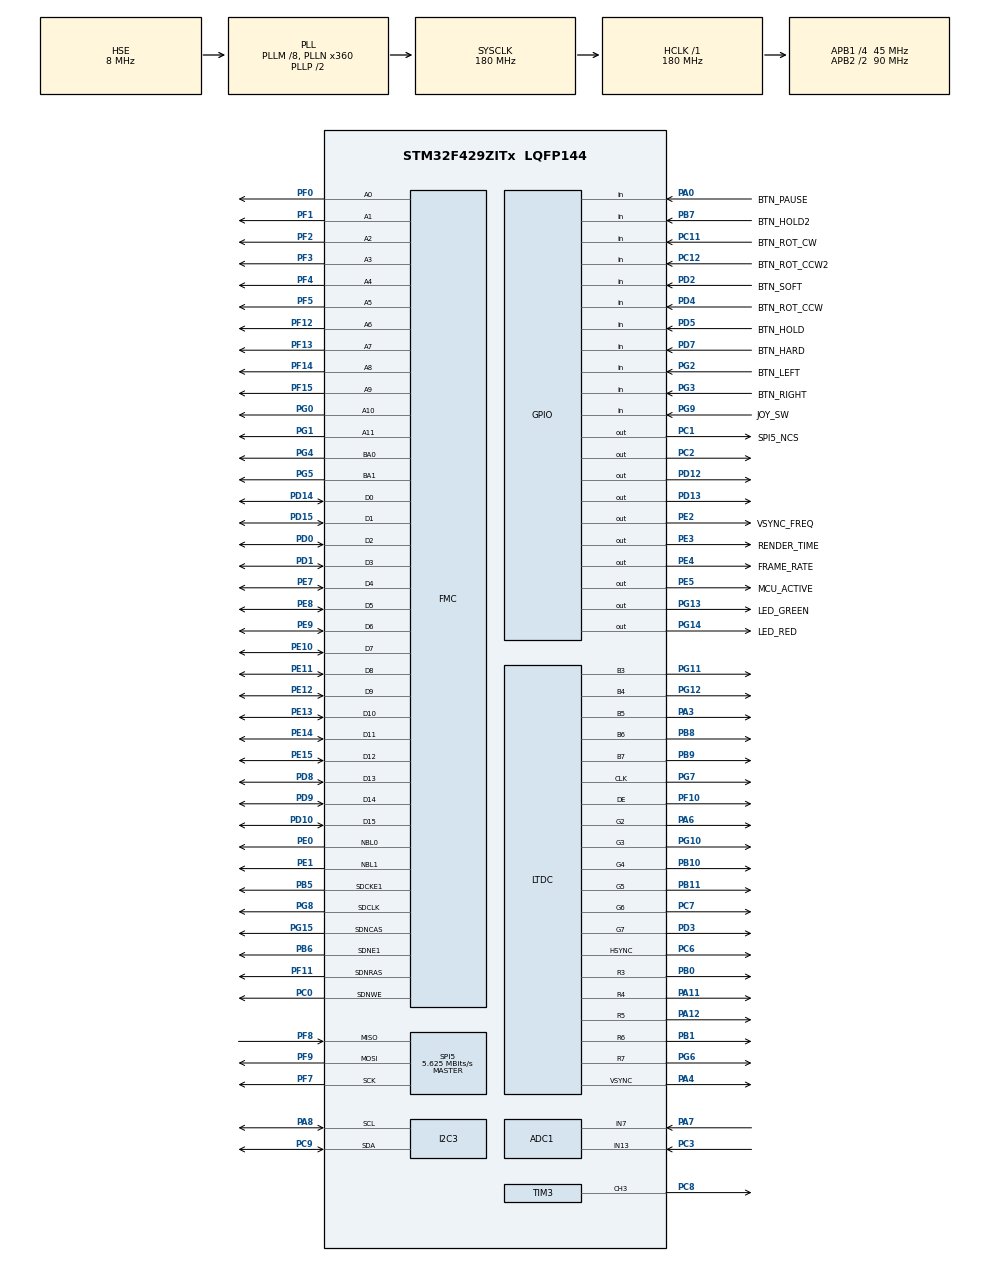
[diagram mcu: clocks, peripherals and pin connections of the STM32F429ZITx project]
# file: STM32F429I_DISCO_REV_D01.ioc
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ADC1.Channel-0\#ChannelRegularConversion=ADC_CHANNEL_13
ADC1.Channel-1\#ChannelRegularConversion=ADC_CHANNEL_7
ADC1.ContinuousConvMode=ENABLE
ADC1.DMAContinuousRequests=ENABLE
ADC1.NbrOfConversion=2
ADC1.NbrOfConversionFlag=1
ADC1.Rank-0\#ChannelRegularConversion=1
ADC1.Rank-1\#ChannelRegularConversion=2
ADC1.SamplingTime-0\#ChannelRegularConversion=ADC_SAMPLETIME_144CYCLES
ADC1.SamplingTime-1\#ChannelRegularConversion=ADC_SAMPLETIME_144CYCLES
ADC1.ScanConvMode=ENABLE
ADC1.master=1
DMA2D.ColorMode=DMA2D_OUTPUT_RGB565
Dma.ADC1.0.Direction=DMA_PERIPH_TO_MEMORY
Dma.ADC1.0.FIFOMode=DMA_FIFOMODE_DISABLE
Dma.ADC1.0.Instance=DMA2_Stream0
Dma.ADC1.0.MemDataAlignment=DMA_MDATAALIGN_HALFWORD
Dma.ADC1.0.MemInc=DMA_MINC_ENABLE
Dma.ADC1.0.Mode=DMA_CIRCULAR
Dma.ADC1.0.PeriphDataAlignment=DMA_PDATAALIGN_HALFWORD
Dma.ADC1.0.PeriphInc=DMA_PINC_DISABLE
Dma.ADC1.0.Priority=DMA_PRIORITY_LOW
Dma.Request0=ADC1
FMC.CASLatency1=FMC_SDRAM_CAS_LATENCY_3
FMC.ExitSelfRefreshDelay1=7
FMC.LoadToActiveDelay1=2
FMC.RCDDelay1=2
FMC.RPDelay1=2
FMC.ReadPipeDelay1=FMC_SDRAM_RPIPE_DELAY_1
FMC.RowCycleDelay1=7
FMC.SDClockPeriod1=FMC_SDRAM_CLOCK_PERIOD_2
FMC.SelfRefreshTime1=4
FMC.WriteRecoveryTime1=3
FREERTOS.Tasks01=defaultTask,24,128,StartDefaultTask,Default,NULL,Dynamic,NULL,NULL;GUI_Task,24,8192,TouchGFX_Task,As external,NULL,Dynamic,NULL,NULL
FREERTOS.configMAX_PRIORITIES=56
FREERTOS.configTOTAL_HEAP_SIZE=65536
FREERTOS.configUSE_APPLICATION_TASK_TAG=1
FREERTOS.configUSE_NEWLIB_REENTRANT=1
I2C3.Analog_Filter=I2C_ANALOGFILTER_DISABLE
LTDC.ActiveH=320
LTDC.ActiveW=240
LTDC.Alpha_L0=255
LTDC.BlendingFactor1_L0=LTDC_BLENDING_FACTOR1_CA
LTDC.BlendingFactor2_L0=LTDC_BLENDING_FACTOR2_CA
LTDC.Blue_L0=0
LTDC.HBP=20
LTDC.HFP=10
LTDC.HSync=10
LTDC.ImageHeight_L0=320
LTDC.ImageWidth_L0=240
LTDC.Layers=0
LTDC.PixelFormat_L0=LTDC_PIXEL_FORMAT_RGB565
LTDC.VFP=4
LTDC.VSync=2
LTDC.WindowX1_L0=240
LTDC.WindowY1_L0=320
Mcu.Family=STM32F4
Mcu.Name=STM32F429ZITx
Mcu.Package=LQFP144
NVIC.DMA2D_IRQn=true\:5\:0\:true\:false\:true\:false\:true\:true\:true
NVIC.DMA2_Stream0_IRQn=true\:5\:0\:false\:false\:true\:true\:false\:true\:true
NVIC.LTDC_IRQn=true\:5\:0\:true\:false\:true\:false\:true\:true\:true
NVIC.PriorityGroup=NVIC_PRIORITYGROUP_4
NVIC.TIM6_DAC_IRQn=true\:0\:0\:false\:false\:true\:false\:false\:true\:true
NVIC.TimeBase=TIM6_DAC_IRQn
NVIC.TimeBaseIP=TIM6
PA0/WKUP.GPIO_Label=BTN_PAUSE
PA0/WKUP.GPIO_PuPd=GPIO_NOPULL
PA0/WKUP.Signal=GPIO_Input
PA11.GPIO_Speed=GPIO_SPEED_FREQ_HIGH
PA11.Mode=RGB565
PA11.Signal=LTDC_R4
PA12.GPIO_Speed=GPIO_SPEED_FREQ_HIGH
PA12.Mode=RGB565
PA12.Signal=LTDC_R5
PA3.GPIO_Speed=GPIO_SPEED_FREQ_HIGH
PA3.Mode=RGB565
PA3.Signal=LTDC_B5
PA4.GPIO_Speed=GPIO_SPEED_FREQ_HIGH
PA4.Mode=RGB565
PA4.Signal=LTDC_VSYNC
PA6.GPIO_Speed=GPIO_SPEED_FREQ_HIGH
PA6.Mode=RGB565
PA6.Signal=LTDC_G2
PA7.Signal=ADCx_IN7
PA8.GPIO_Pu=GPIO_PULLUP
PA8.Mode=I2C
PA8.Signal=I2C3_SCL
PB0.GPIO_Speed=GPIO_SPEED_FREQ_HIGH
PB0.Mode=RGB565
PB0.Signal=LTDC_R3
PB1.GPIO_Speed=GPIO_SPEED_FREQ_HIGH
PB1.Mode=RGB565
PB1.Signal=LTDC_R6
PB10.GPIO_Speed=GPIO_SPEED_FREQ_HIGH
PB10.Mode=RGB565
PB10.Signal=LTDC_G4
PB11.GPIO_Speed=GPIO_SPEED_FREQ_HIGH
PB11.Mode=RGB565
PB11.Signal=LTDC_G5
PB5.Mode=SdramChipSelect2_1
PB5.Signal=FMC_SDCKE1
PB6.Mode=SdramChipSelect2_1
PB6.Signal=FMC_SDNE1
PB7.GPIO_Label=BTN_HOLD2
PB7.GPIO_PuPd=GPIO_PULLUP
PB7.Signal=GPIO_Input
PB8.GPIO_Speed=GPIO_SPEED_FREQ_HIGH
PB8.Mode=RGB565
PB8.Signal=LTDC_B6
PB9.GPIO_Speed=GPIO_SPEED_FREQ_HIGH
PB9.Mode=RGB565
PB9.Signal=LTDC_B7
PC0.Signal=FMC_SDNWE
PC1.GPIO_Label=SPI5_NCS
PC1.PinState=GPIO_PIN_SET
PC1.Signal=GPIO_Output
PC11.GPIO_Label=BTN_ROT_CW
PC11.GPIO_PuPd=GPIO_PULLUP
PC11.Signal=GPIO_Input
PC12.GPIO_Label=BTN_ROT_CCW2
PC12.GPIO_PuPd=GPIO_PULLUP
PC12.Signal=GPIO_Input
PC2.GPIO_Speed=GPIO_SPEED_FREQ_HIGH
PC2.Signal=GPIO_Output
PC3.Signal=ADCx_IN13
PC6.GPIO_Speed=GPIO_SPEED_FREQ_HIGH
PC6.Mode=RGB565
PC6.Signal=LTDC_HSYNC
PC7.GPIO_Speed=GPIO_SPEED_FREQ_HIGH
PC7.Mode=RGB565
PC7.Signal=LTDC_G6
PC8.Signal=S_TIM3_CH3
PC9.GPIO_Pu=GPIO_PULLUP
PC9.Mode=I2C
PC9.Signal=I2C3_SDA
PD0.Signal=FMC_D2_DA2
PD1.Signal=FMC_D3_DA3
PD10.Signal=FMC_D15_DA15
PD12.GPIO_Speed=GPIO_SPEED_FREQ_HIGH
PD12.Signal=GPIO_Output
PD13.GPIO_Speed=GPIO_SPEED_FREQ_HIGH
PD13.Signal=GPIO_Output
PD14.Signal=FMC_D0_DA0
PD15.Signal=FMC_D1_DA1
PD2.GPIO_Label=BTN_SOFT
PD2.GPIO_PuPd=GPIO_PULLUP
PD2.Signal=GPIO_Input
PD3.GPIO_Speed=GPIO_SPEED_FREQ_HIGH
PD3.Mode=RGB565
PD3.Signal=LTDC_G7
PD4.GPIO_Label=BTN_ROT_CCW
PD4.GPIO_PuPd=GPIO_PULLUP
PD4.Signal=GPIO_Input
PD5.GPIO_Label=BTN_HOLD
PD5.GPIO_PuPd=GPIO_PULLUP
PD5.Signal=GPIO_Input
PD7.GPIO_Label=BTN_HARD
PD7.GPIO_PuPd=GPIO_PULLUP
PD7.Signal=GPIO_Input
PD8.Signal=FMC_D13_DA13
PD9.Signal=FMC_D14_DA14
PE0.Signal=FMC_NBL0
PE1.Signal=FMC_NBL1
PE10.Signal=FMC_D7_DA7
PE11.Signal=FMC_D8_DA8
PE12.Signal=FMC_D9_DA9
PE13.Signal=FMC_D10_DA10
PE14.Signal=FMC_D11_DA11
PE15.Signal=FMC_D12_DA12
PE2.GPIO_Label=VSYNC_FREQ
PE2.GPIO_Speed=GPIO_SPEED_FREQ_VERY_HIGH
PE2.Signal=GPIO_Output
PE3.GPIO_Label=RENDER_TIME
PE3.GPIO_Speed=GPIO_SPEED_FREQ_VERY_HIGH
PE3.Signal=GPIO_Output
PE4.GPIO_Label=FRAME_RATE
PE4.GPIO_Speed=GPIO_SPEED_FREQ_VERY_HIGH
PE4.Signal=GPIO_Output
PE5.GPIO_Label=MCU_ACTIVE
PE5.GPIO_Speed=GPIO_SPEED_FREQ_VERY_HIGH
PE5.Signal=GPIO_Output
PE7.Signal=FMC_D4_DA4
PE8.Signal=FMC_D5_DA5
PE9.Signal=FMC_D6_DA6
PF0.Signal=FMC_A0
PF1.Signal=FMC_A1
PF10.GPIO_Speed=GPIO_SPEED_FREQ_HIGH
PF10.Mode=RGB565
PF10.Signal=LTDC_DE
PF11.Signal=FMC_SDNRAS
PF12.Signal=FMC_A6
PF13.Signal=FMC_A7
PF14.Signal=FMC_A8
PF15.Signal=FMC_A9
PF2.Signal=FMC_A2
PF3.Signal=FMC_A3
PF4.Signal=FMC_A4
PF5.Signal=FMC_A5
PF7.Mode=Full_Duplex_Master
PF7.Signal=SPI5_SCK
PF8.Mode=Full_Duplex_Master
PF8.Signal=SPI5_MISO
PF9.Mode=Full_Duplex_Master
PF9.Signal=SPI5_MOSI
PG0.Signal=FMC_A10
PG1.Signal=FMC_A11
PG10.GPIO_Speed=GPIO_SPEED_FREQ_HIGH
PG10.Mode=RGB565
PG10.Signal=LTDC_G3
PG11.GPIO_Speed=GPIO_SPEED_FREQ_HIGH
PG11.Mode=RGB565
PG11.Signal=LTDC_B3
PG12.GPIO_Speed=GPIO_SPEED_FREQ_HIGH
PG12.Mode=RGB565
PG12.Signal=LTDC_B4
PG13.GPIO_Label=LED_GREEN
PG13.GPIO_ModeDefaultOutputPP=GPIO_MODE_OUTPUT_PP
PG13.PinState=GPIO_PIN_RESET
PG13.Signal=GPIO_Output
PG14.GPIO_Label=LED_RED
PG14.GPIO_ModeDefaultOutputPP=GPIO_MODE_OUTPUT_PP
PG14.PinState=GPIO_PIN_RESET
PG14.Signal=GPIO_Output
PG15.Signal=FMC_SDNCAS
PG2.GPIO_Label=BTN_LEFT
PG2.GPIO_PuPd=GPIO_PULLUP
PG2.Signal=GPIO_Input
PG3.GPIO_Label=BTN_RIGHT
PG3.GPIO_PuPd=GPIO_PULLUP
PG3.Signal=GPIO_Input
PG4.Signal=FMC_A14_BA0
PG5.Signal=FMC_A15_BA1
PG6.GPIO_Speed=GPIO_SPEED_FREQ_HIGH
PG6.Mode=RGB565
PG6.Signal=LTDC_R7
PG7.GPIO_Speed=GPIO_SPEED_FREQ_HIGH
PG7.Mode=RGB565
PG7.Signal=LTDC_CLK
PG8.Signal=FMC_SDCLK
PG9.GPIO_Label=JOY_SW
PG9.GPIO_PuPd=GPIO_PULLUP
PG9.Signal=GPIO_Input
PH0/OSC_IN.Mode=HSE-External-Oscillator
PH0/OSC_IN.Signal=RCC_OSC_IN
PH1/OSC_OUT.Mode=HSE-External-Oscillator
PH1/OSC_OUT.Signal=RCC_OSC_OUT
ProjectManager.HeapSize=0xA00
ProjectManager.StackSize=0xA00
ProjectManager.TargetToolchain=STM32CubeIDE
RCC.48MHZClocksFreq_Value=90000000
RCC.AHBFreq_Value=180000000
RCC.APB1CLKDivider=RCC_HCLK_DIV4
RCC.APB1Freq_Value=45000000
RCC.APB1TimFreq_Value=90000000
RCC.APB2CLKDivider=RCC_HCLK_DIV2
RCC.APB2Freq_Value=90000000
RCC.APB2TimFreq_Value=180000000
RCC.CortexFreq_Value=180000000
RCC.HCLKFreq_Value=180000000
RCC.HSE_VALUE=8000000
RCC.HSI_VALUE=16000000
RCC.LSE_VALUE=32768
RCC.PLLM=8
RCC.PLLN=360
RCC.PLLSAIDivR=RCC_PLLSAIDIVR_8
RCC.PLLSAIN=192
RCC.PLLSAIR=4
RCC.PLLSourceVirtual=RCC_PLLSOURCE_HSE
RCC.SYSCLKFreq_VALUE=180000000
RCC.SYSCLKSource=RCC_SYSCLKSOURCE_PLLCLK
RCC.VCOOutputFreq_Value=360000000
SH.ADCx_IN13.0=ADC1_IN13,IN13
SH.ADCx_IN7.0=ADC1_IN7,IN7
SH.FMC_A0.0=FMC_A0,12b-sda1
SH.FMC_A1.0=FMC_A1,12b-sda1
SH.FMC_A10.0=FMC_A10,12b-sda1
SH.FMC_A11.0=FMC_A11,12b-sda1
SH.FMC_A14_BA0.0=FMC_BA0,FourSdramBanks1
SH.FMC_A15_BA1.0=FMC_BA1,FourSdramBanks1
SH.FMC_A2.0=FMC_A2,12b-sda1
SH.FMC_A3.0=FMC_A3,12b-sda1
SH.FMC_A4.0=FMC_A4,12b-sda1
SH.FMC_A5.0=FMC_A5,12b-sda1
SH.FMC_A6.0=FMC_A6,12b-sda1
SH.FMC_A7.0=FMC_A7,12b-sda1
SH.FMC_A8.0=FMC_A8,12b-sda1
SH.FMC_A9.0=FMC_A9,12b-sda1
SH.FMC_D0_DA0.0=FMC_D0,sd-16b-d1
SH.FMC_D10_DA10.0=FMC_D10,sd-16b-d1
SH.FMC_D11_DA11.0=FMC_D11,sd-16b-d1
SH.FMC_D12_DA12.0=FMC_D12,sd-16b-d1
SH.FMC_D13_DA13.0=FMC_D13,sd-16b-d1
SH.FMC_D14_DA14.0=FMC_D14,sd-16b-d1
SH.FMC_D15_DA15.0=FMC_D15,sd-16b-d1
SH.FMC_D1_DA1.0=FMC_D1,sd-16b-d1
SH.FMC_D2_DA2.0=FMC_D2,sd-16b-d1
SH.FMC_D3_DA3.0=FMC_D3,sd-16b-d1
SH.FMC_D4_DA4.0=FMC_D4,sd-16b-d1
SH.FMC_D5_DA5.0=FMC_D5,sd-16b-d1
SH.FMC_D6_DA6.0=FMC_D6,sd-16b-d1
SH.FMC_D7_DA7.0=FMC_D7,sd-16b-d1
SH.FMC_D8_DA8.0=FMC_D8,sd-16b-d1
SH.FMC_D9_DA9.0=FMC_D9,sd-16b-d1
SH.FMC_NBL0.0=FMC_NBL0,Sd2ByteEnable1
SH.FMC_NBL1.0=FMC_NBL1,Sd2ByteEnable1
SH.FMC_SDCLK.0=FMC_SDCLK,12b-sda1
SH.FMC_SDNCAS.0=FMC_SDNCAS,12b-sda1
SH.FMC_SDNRAS.0=FMC_SDNRAS,12b-sda1
SH.FMC_SDNWE.0=FMC_SDNWE,12b-sda1
SH.S_TIM3_CH3.0=TIM3_CH3,PWM Generation3 CH3
SPI5.BaudRatePrescaler=SPI_BAUDRATEPRESCALER_16
SPI5.CLKPolarity=SPI_POLARITY_LOW
SPI5.CRCCalculation=SPI_CRCCALCULATION_DISABLE
SPI5.CalculateBaudRate=5.625 MBits/s
SPI5.Direction=SPI_DIRECTION_2LINES
SPI5.Mode=SPI_MODE_MASTER
SPI5.VirtualType=VM_MASTER
STMicroelectronics.X-CUBE-TOUCHGFX.4.25.0.ApplicationCcGraphicsJjApplication=TouchGFXOoGenerator
STMicroelectronics.X-CUBE-TOUCHGFX.4.25.0.tgfx_buffering_strategy=Double
STMicroelectronics.X-CUBE-TOUCHGFX.4.25.0.tgfx_display_interface=disp_ltdc
STMicroelectronics.X-CUBE-TOUCHGFX.4.25.0.tgfx_hardware_accelerator=dma_2d
STMicroelectronics.X-CUBE-TOUCHGFX.4.25.0.tgfx_vector_fonts=Enabled
STMicroelectronics.X-CUBE-TOUCHGFX.4.25.0.tgfx_vector_rendering=Software
STMicroelectronics.X-CUBE-TOUCHGFX.4.25.0.tgfx_vsync=vsync_ltdc
TIM3.Channel-PWM\ Generation3\ CH3=TIM_CHANNEL_3
TIM3.Period=999
TIM3.Prescaler=89
TIM3.Pulse-PWM\ Generation3\ CH3=500
VP_CRC_VS_CRC.Mode=CRC_Activate
VP_DMA2D_VS_DMA2D.Mode=DMA2D_Activate
VP_FREERTOS_VS_CMSIS_V2.Mode=CMSIS_V2
VP_RNG_VS_RNG.Mode=RNG_Activate
VP_STMicroelectronics.X-CUBE-TOUCHGFX_VS_GraphicsJjApplication_4.25.0.Mode=GraphicsJjApplication
VP_SYS_VS_tim6.Mode=TIM6
VP_TIM3_VS_ClockSourceINT.Mode=Internal
board=custom

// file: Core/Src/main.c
/* USER CODE BEGIN Header */
/**
  ******************************************************************************
  * @file           : main.c
  * @brief          : Main program body
  ******************************************************************************
  * @attention
  *
  * <h2><center>&copy; Copyright (c) 2020 STMicroelectronics.
  * All rights reserved.</center></h2>
  *
  * This software component is licensed by ST under Ultimate Liberty license
  * SLA0044, the "License"; You may not use this file except in compliance with
  * the License. You may obtain a copy of the License at:
  *                             www.st.com/SLA0044
  *
  ******************************************************************************
  */
/* USER CODE END Header */
#include "main.h"
#include "cmsis_os.h"
#include "app_touchgfx.h"

/* USER CODE BEGIN Includes */
#include "Components/ili9341/ili9341.h"
/* USER CODE END Includes */

/* USER CODE BEGIN PD */
#define REFRESH_COUNT           ((uint32_t)1386)   /* SDRAM refresh counter */
#define SDRAM_TIMEOUT           ((uint32_t)0xFFFF)

/**
  * @brief  FMC SDRAM Mode definition register defines
  */
#define SDRAM_MODEREG_BURST_LENGTH_1             ((uint16_t)0x0000)
#define SDRAM_MODEREG_BURST_LENGTH_2             ((uint16_t)0x0001)
#define SDRAM_MODEREG_BURST_LENGTH_4             ((uint16_t)0x0002)
#define SDRAM_MODEREG_BURST_LENGTH_8             ((uint16_t)0x0004)
#define SDRAM_MODEREG_BURST_TYPE_SEQUENTIAL      ((uint16_t)0x0000)
#define SDRAM_MODEREG_BURST_TYPE_INTERLEAVED     ((uint16_t)0x0008)
#define SDRAM_MODEREG_CAS_LATENCY_2              ((uint16_t)0x0020)
#define SDRAM_MODEREG_CAS_LATENCY_3              ((uint16_t)0x0030)
#define SDRAM_MODEREG_OPERATING_MODE_STANDARD    ((uint16_t)0x0000)
#define SDRAM_MODEREG_WRITEBURST_MODE_PROGRAMMED ((uint16_t)0x0000)
#define SDRAM_MODEREG_WRITEBURST_MODE_SINGLE     ((uint16_t)0x0200)

#define I2C3_TIMEOUT_MAX                    0x3000 /*<! The value of the maximal timeout for I2C waiting loops */
#define SPI5_TIMEOUT_MAX                    0x1000
/* USER CODE END PD */

ADC_HandleTypeDef hadc1;
DMA_HandleTypeDef hdma_adc1;

CRC_HandleTypeDef hcrc;

DMA2D_HandleTypeDef hdma2d;

I2C_HandleTypeDef hi2c3;

LTDC_HandleTypeDef hltdc;

RNG_HandleTypeDef hrng;

SPI_HandleTypeDef hspi5;

TIM_HandleTypeDef htim3;

SDRAM_HandleTypeDef hsdram1;

/* Definitions for defaultTask */
osThreadId_t defaultTaskHandle;
const osThreadAttr_t defaultTask_attributes = {
  .name = "defaultTask",
  .stack_size = 128 * 4,
  .priority = (osPriority_t) osPriorityNormal,
};
/* Definitions for GUI_Task */
osThreadId_t GUI_TaskHandle;
const osThreadAttr_t GUI_Task_attributes = {
  .name = "GUI_Task",
  .stack_size = 8192 * 4,
  .priority = (osPriority_t) osPriorityNormal,
};
/* USER CODE BEGIN PV */
uint8_t isRevD = 0; /* Applicable only for STM32F429I DISCOVERY REVD and above */

/* Tetris P4 - input phần cứng: joystick ADC (DMA đổ) + hàng đợi lệnh -> GUI task */
uint16_t g_adcJoy[2] = { 2048, 2048 }; /* [0]=VRx (PC3), [1]=VRy (PA7) */
osMessageQueueId_t inputQueueHandle = NULL;

/* Tetris P6 - âm thanh: hàng đợi sự kiện âm + cờ bật nhạc + AudioTask (buzzer TIM3 PWM) */
osMessageQueueId_t soundQueueHandle = NULL;
uint8_t g_soundOn = 1; /* 1 = bật nhạc nền Korobeiniki */
uint8_t g_musicPaused = 0; /* 1 = tạm dừng nhạc nền (khi game Pause) */
uint8_t g_pvpMode = 0;     /* 1 = chế độ 2 người: nút=P1 (mã 0..5), joystick=P2 (mã 16..21) */
osThreadId_t audioTaskHandle;
const osThreadAttr_t audioTask_attributes = {
  .name = "audioTask",
  .stack_size = 256 * 4,
  .priority = (osPriority_t) osPriorityLow,
};
/* USER CODE END PV */

void SystemClock_Config(void);
static void MX_GPIO_Init(void);
static void MX_DMA_Init(void);
static void MX_CRC_Init(void);
static void MX_I2C3_Init(void);
static void MX_SPI5_Init(void);
static void MX_FMC_Init(void);
static void MX_LTDC_Init(void);
static void MX_DMA2D_Init(void);
static void MX_ADC1_Init(void);
static void MX_RNG_Init(void);
static void MX_TIM3_Init(void);
void StartDefaultTask(void *argument);
extern void TouchGFX_Task(void *argument);

/* USER CODE BEGIN PFP */
void StartAudioTask(void *argument); /* P6: task phát âm thanh qua buzzer */
static void BSP_SDRAM_Initialization_Sequence(SDRAM_HandleTypeDef *hsdram, FMC_SDRAM_CommandTypeDef *Command);

static uint8_t            I2C3_ReadData(uint8_t Addr, uint8_t Reg);
static void               I2C3_WriteData(uint8_t Addr, uint8_t Reg, uint8_t Value);
static uint8_t            I2C3_ReadBuffer(uint8_t Addr, uint8_t Reg, uint8_t *pBuffer, uint16_t Length);

/* SPIx bus function */
static void               SPI5_Write(uint16_t Value);
static uint32_t           SPI5_Read(uint8_t ReadSize);
static void               SPI5_Error(void);

/* Link function for LCD peripheral */
void                      LCD_IO_Init(void);
void                      LCD_IO_WriteData(uint16_t RegValue);
void                      LCD_IO_WriteReg(uint8_t Reg);
uint32_t                  LCD_IO_ReadData(uint16_t RegValue, uint8_t ReadSize);
void                      LCD_Delay(uint32_t delay);

/* IOExpander IO functions */
void                      IOE_Init(void);
void                      IOE_ITConfig(void);
void                      IOE_Delay(uint32_t Delay);
void                      IOE_Write(uint8_t Addr, uint8_t Reg, uint8_t Value);
uint8_t                   IOE_Read(uint8_t Addr, uint8_t Reg);
uint16_t                  IOE_ReadMultiple(uint8_t Addr, uint8_t Reg, uint8_t *pBuffer, uint16_t Length);

/* USER CODE END PFP */

/* USER CODE BEGIN 0 */
static LCD_DrvTypeDef* LcdDrv;

uint32_t I2c3Timeout = I2C3_TIMEOUT_MAX; /*<! Value of Timeout when I2C communication fails */
uint32_t Spi5Timeout = SPI5_TIMEOUT_MAX; /*<! Value of Timeout when SPI communication fails */
/* USER CODE END 0 */

int main(void)
{

  /* MCU Configuration--------------------------------------------------------*/

  /* Reset of all peripherals, Initializes the Flash interface and the Systick. */
  HAL_Init();

  /* Configure the system clock */
  SystemClock_Config();

  /* Initialize all configured peripherals */
  MX_GPIO_Init();
  MX_DMA_Init();
  MX_CRC_Init();
  MX_I2C3_Init();
  MX_SPI5_Init();
  MX_FMC_Init();
  MX_LTDC_Init();
  MX_DMA2D_Init();
  MX_ADC1_Init();
  MX_RNG_Init();
  MX_TIM3_Init();
  MX_TouchGFX_Init();
  /* Call PreOsInit function */
  MX_TouchGFX_PreOSInit();
  /* USER CODE BEGIN 2 */
  /* Joystick: ADC1 2 kênh chạy DMA vòng -> tự đổ liên tục vào g_adcJoy[] */
  HAL_ADC_Start_DMA(&hadc1, (uint32_t*)g_adcJoy, 2);
  /* Buzzer: bật kênh PWM TIM3_CH3 (PC8), im lặng ban đầu (duty 0) */
  HAL_TIM_PWM_Start(&htim3, TIM_CHANNEL_3);
  __HAL_TIM_SET_COMPARE(&htim3, TIM_CHANNEL_3, 0);
  /* Nút HOLD P2 (PB7, PvP) được cấu hình trong CubeMX (label BTN_HOLD2, Input + Pull-up)
     -> MX_GPIO_Init lo việc init; ở đây không cần làm gì thêm. */
  /* USER CODE END 2 */

  /* Init scheduler */
  osKernelInitialize();

  /* USER CODE BEGIN RTOS_QUEUES */
  /* Hàng đợi lệnh điều khiển (mã 0..5 KHỚP enum tetris::Command) */
  inputQueueHandle = osMessageQueueNew(16, sizeof(uint8_t), NULL);
  /* Hàng đợi sự kiện âm (mã KHỚP enum tetris::Sound). Sâu 32 để hứng cao điểm PvP (2 người). */
  soundQueueHandle = osMessageQueueNew(32, sizeof(uint8_t), NULL);
  /* USER CODE END RTOS_QUEUES */

  /* Create the thread(s) */
  /* creation of defaultTask */
  defaultTaskHandle = osThreadNew(StartDefaultTask, NULL, &defaultTask_attributes);

  /* creation of GUI_Task */
  GUI_TaskHandle = osThreadNew(TouchGFX_Task, NULL, &GUI_Task_attributes);

  /* USER CODE BEGIN RTOS_THREADS */
  audioTaskHandle = osThreadNew(StartAudioTask, NULL, &audioTask_attributes);
  /* USER CODE END RTOS_THREADS */

  /* Start scheduler */
  osKernelStart();

  /* We should never get here as control is now taken by the scheduler */

  /* Infinite loop */
  while (1)
  {

  }
}

void SystemClock_Config(void)
{
  RCC_OscInitTypeDef RCC_OscInitStruct = {0};
  RCC_ClkInitTypeDef RCC_ClkInitStruct = {0};

  /** Configure the main internal regulator output voltage
  */
  __HAL_RCC_PWR_CLK_ENABLE();
  __HAL_PWR_VOLTAGESCALING_CONFIG(PWR_REGULATOR_VOLTAGE_SCALE1);

  /** Initializes the RCC Oscillators according to the specified parameters
  * in the RCC_OscInitTypeDef structure.
  */
  RCC_OscInitStruct.OscillatorType = RCC_OSCILLATORTYPE_HSE;
  RCC_OscInitStruct.HSEState = RCC_HSE_ON;
  RCC_OscInitStruct.PLL.PLLState = RCC_PLL_ON;
  RCC_OscInitStruct.PLL.PLLSource = RCC_PLLSOURCE_HSE;
  RCC_OscInitStruct.PLL.PLLM = 8;
  RCC_OscInitStruct.PLL.PLLN = 360;
  RCC_OscInitStruct.PLL.PLLP = RCC_PLLP_DIV2;
  RCC_OscInitStruct.PLL.PLLQ = 4;
  if (HAL_RCC_OscConfig(&RCC_OscInitStruct) != HAL_OK)
  {
    Error_Handler();
  }

  /** Activate the Over-Drive mode
  */
  if (HAL_PWREx_EnableOverDrive() != HAL_OK)
  {
    Error_Handler();
  }

  /** Initializes the CPU, AHB and APB buses clocks
  */
  RCC_ClkInitStruct.ClockType = RCC_CLOCKTYPE_HCLK|RCC_CLOCKTYPE_SYSCLK
                              |RCC_CLOCKTYPE_PCLK1|RCC_CLOCKTYPE_PCLK2;
  RCC_ClkInitStruct.SYSCLKSource = RCC_SYSCLKSOURCE_PLLCLK;
  RCC_ClkInitStruct.AHBCLKDivider = RCC_SYSCLK_DIV1;
  RCC_ClkInitStruct.APB1CLKDivider = RCC_HCLK_DIV4;
  RCC_ClkInitStruct.APB2CLKDivider = RCC_HCLK_DIV2;

  if (HAL_RCC_ClockConfig(&RCC_ClkInitStruct, FLASH_LATENCY_5) != HAL_OK)
  {
    Error_Handler();
  }
}

static void MX_ADC1_Init(void)
{

  ADC_ChannelConfTypeDef sConfig = {0};

  /** Configure the global features of the ADC (Clock, Resolution, Data Alignment and number of conversion)
  */
  hadc1.Instance = ADC1;
  hadc1.Init.ClockPrescaler = ADC_CLOCK_SYNC_PCLK_DIV4;
  hadc1.Init.Resolution = ADC_RESOLUTION_12B;
  hadc1.Init.ScanConvMode = ENABLE;
  hadc1.Init.ContinuousConvMode = ENABLE;
  hadc1.Init.DiscontinuousConvMode = DISABLE;
  hadc1.Init.ExternalTrigConvEdge = ADC_EXTERNALTRIGCONVEDGE_NONE;
  hadc1.Init.ExternalTrigConv = ADC_SOFTWARE_START;
  hadc1.Init.DataAlign = ADC_DATAALIGN_RIGHT;
  hadc1.Init.NbrOfConversion = 2;
  hadc1.Init.DMAContinuousRequests = ENABLE;
  hadc1.Init.EOCSelection = ADC_EOC_SINGLE_CONV;
  if (HAL_ADC_Init(&hadc1) != HAL_OK)
  {
    Error_Handler();
  }

  /** Configure for the selected ADC regular channel its corresponding rank in the sequencer and its sample time.
  */
  sConfig.Channel = ADC_CHANNEL_13;
  sConfig.Rank = 1;
  sConfig.SamplingTime = ADC_SAMPLETIME_144CYCLES;
  if (HAL_ADC_ConfigChannel(&hadc1, &sConfig) != HAL_OK)
  {
    Error_Handler();
  }

  /** Configure for the selected ADC regular channel its corresponding rank in the sequencer and its sample time.
  */
  sConfig.Channel = ADC_CHANNEL_7;
  sConfig.Rank = 2;
  if (HAL_ADC_ConfigChannel(&hadc1, &sConfig) != HAL_OK)
  {
    Error_Handler();
  }

}

static void MX_CRC_Init(void)
{

  hcrc.Instance = CRC;
  if (HAL_CRC_Init(&hcrc) != HAL_OK)
  {
    Error_Handler();
  }

}

static void MX_DMA2D_Init(void)
{

  hdma2d.Instance = DMA2D;
  hdma2d.Init.Mode = DMA2D_M2M;
  hdma2d.Init.ColorMode = DMA2D_OUTPUT_RGB565;
  hdma2d.Init.OutputOffset = 0;
  hdma2d.LayerCfg[1].InputOffset = 0;
  hdma2d.LayerCfg[1].InputColorMode = DMA2D_INPUT_RGB565;
  hdma2d.LayerCfg[1].AlphaMode = DMA2D_NO_MODIF_ALPHA;
  hdma2d.LayerCfg[1].InputAlpha = 0;
  if (HAL_DMA2D_Init(&hdma2d) != HAL_OK)
  {
    Error_Handler();
  }
  if (HAL_DMA2D_ConfigLayer(&hdma2d, 1) != HAL_OK)
  {
    Error_Handler();
  }

}

static void MX_I2C3_Init(void)
{

  hi2c3.Instance = I2C3;
  hi2c3.Init.ClockSpeed = 100000;
  hi2c3.Init.DutyCycle = I2C_DUTYCYCLE_2;
  hi2c3.Init.OwnAddress1 = 0;
  hi2c3.Init.AddressingMode = I2C_ADDRESSINGMODE_7BIT;
  hi2c3.Init.DualAddressMode = I2C_DUALADDRESS_DISABLE;
  hi2c3.Init.OwnAddress2 = 0;
  hi2c3.Init.GeneralCallMode = I2C_GENERALCALL_DISABLE;
  hi2c3.Init.NoStretchMode = I2C_NOSTRETCH_DISABLE;
  if (HAL_I2C_Init(&hi2c3) != HAL_OK)
  {
    Error_Handler();
  }

  /** Configure Analogue filter
  */
  if (HAL_I2CEx_ConfigAnalogFilter(&hi2c3, I2C_ANALOGFILTER_DISABLE) != HAL_OK)
  {
    Error_Handler();
  }

  /** Configure Digital filter
  */
  if (HAL_I2CEx_ConfigDigitalFilter(&hi2c3, 0) != HAL_OK)
  {
    Error_Handler();
  }

}

static void MX_LTDC_Init(void)
{

  LTDC_LayerCfgTypeDef pLayerCfg = {0};

  hltdc.Instance = LTDC;
  hltdc.Init.HSPolarity = LTDC_HSPOLARITY_AL;
  hltdc.Init.VSPolarity = LTDC_VSPOLARITY_AL;
  hltdc.Init.DEPolarity = LTDC_DEPOLARITY_AL;
  hltdc.Init.PCPolarity = LTDC_PCPOLARITY_IPC;
  hltdc.Init.HorizontalSync = 9;
  hltdc.Init.VerticalSync = 1;
  hltdc.Init.AccumulatedHBP = 29;
  hltdc.Init.AccumulatedVBP = 3;
  hltdc.Init.AccumulatedActiveW = 269;
  hltdc.Init.AccumulatedActiveH = 323;
  hltdc.Init.TotalWidth = 279;
  hltdc.Init.TotalHeigh = 327;
  hltdc.Init.Backcolor.Blue = 0;
  hltdc.Init.Backcolor.Green = 0;
  hltdc.Init.Backcolor.Red = 0;
  if (HAL_LTDC_Init(&hltdc) != HAL_OK)
  {
    Error_Handler();
  }
  pLayerCfg.WindowX0 = 0;
  pLayerCfg.WindowX1 = 240;
  pLayerCfg.WindowY0 = 0;
  pLayerCfg.WindowY1 = 320;
  pLayerCfg.PixelFormat = LTDC_PIXEL_FORMAT_RGB565;
  pLayerCfg.Alpha = 255;
  pLayerCfg.Alpha0 = 0;
  pLayerCfg.BlendingFactor1 = LTDC_BLENDING_FACTOR1_CA;
  pLayerCfg.BlendingFactor2 = LTDC_BLENDING_FACTOR2_CA;
  pLayerCfg.FBStartAdress = 0;
  pLayerCfg.ImageWidth = 240;
  pLayerCfg.ImageHeight = 320;
  pLayerCfg.Backcolor.Blue = 0;
  pLayerCfg.Backcolor.Green = 0;
  pLayerCfg.Backcolor.Red = 0;
  if (HAL_LTDC_ConfigLayer(&hltdc, &pLayerCfg, 0) != HAL_OK)
  {
    Error_Handler();
  }
  /* USER CODE BEGIN LTDC_Init 2 */
    /*Select the device */
  LcdDrv = &ili9341_drv;
  /* LCD Init */
  LcdDrv->Init();

  LcdDrv->DisplayOff();
  /* USER CODE END LTDC_Init 2 */

}

static void MX_RNG_Init(void)
{

  hrng.Instance = RNG;
  if (HAL_RNG_Init(&hrng) != HAL_OK)
  {
    Error_Handler();
  }

}

static void MX_SPI5_Init(void)
{

  /* SPI5 parameter configuration*/
  hspi5.Instance = SPI5;
  hspi5.Init.Mode = SPI_MODE_MASTER;
  hspi5.Init.Direction = SPI_DIRECTION_2LINES;
  hspi5.Init.DataSize = SPI_DATASIZE_8BIT;
  hspi5.Init.CLKPolarity = SPI_POLARITY_LOW;
  hspi5.Init.CLKPhase = SPI_PHASE_1EDGE;
  hspi5.Init.NSS = SPI_NSS_SOFT;
  hspi5.Init.BaudRatePrescaler = SPI_BAUDRATEPRESCALER_16;
  hspi5.Init.FirstBit = SPI_FIRSTBIT_MSB;
  hspi5.Init.TIMode = SPI_TIMODE_DISABLE;
  hspi5.Init.CRCCalculation = SPI_CRCCALCULATION_DISABLE;
  hspi5.Init.CRCPolynomial = 10;
  if (HAL_SPI_Init(&hspi5) != HAL_OK)
  {
    Error_Handler();
  }
  /* USER CODE BEGIN SPI5_Init 2 */
  // Check if the board has the old or new revision of the gyroscope
  // This tells if the board is revision D or newer
  // It is used to handle the touch input correctly
  const uint8_t READ_ID_CMD = 0x8F; // 0b10001111 = set read bit and register address of WHO_AM_I
  uint8_t pdata = 0;
  HAL_GPIO_WritePin(SPI5_NCS_GPIO_Port, SPI5_NCS_Pin, GPIO_PIN_RESET);
  HAL_SPI_Transmit(&hspi5, &READ_ID_CMD, 1, 1000);
  HAL_SPI_Receive(&hspi5, &pdata, 1, 1000);
  HAL_GPIO_WritePin(SPI5_NCS_GPIO_Port, SPI5_NCS_Pin, GPIO_PIN_SET);
  if (pdata == 0xD3) // 0b11010011
  {
    isRevD = 1;
  }
  /* USER CODE END SPI5_Init 2 */

}

static void MX_TIM3_Init(void)
{

  TIM_ClockConfigTypeDef sClockSourceConfig = {0};
  TIM_MasterConfigTypeDef sMasterConfig = {0};
  TIM_OC_InitTypeDef sConfigOC = {0};

  htim3.Instance = TIM3;
  htim3.Init.Prescaler = 89;
  htim3.Init.CounterMode = TIM_COUNTERMODE_UP;
  htim3.Init.Period = 999;
  htim3.Init.ClockDivision = TIM_CLOCKDIVISION_DIV1;
  htim3.Init.AutoReloadPreload = TIM_AUTORELOAD_PRELOAD_DISABLE;
  if (HAL_TIM_Base_Init(&htim3) != HAL_OK)
  {
    Error_Handler();
  }
  sClockSourceConfig.ClockSource = TIM_CLOCKSOURCE_INTERNAL;
  if (HAL_TIM_ConfigClockSource(&htim3, &sClockSourceConfig) != HAL_OK)
  {
    Error_Handler();
  }
  if (HAL_TIM_PWM_Init(&htim3) != HAL_OK)
  {
    Error_Handler();
  }
  sMasterConfig.MasterOutputTrigger = TIM_TRGO_RESET;
  sMasterConfig.MasterSlaveMode = TIM_MASTERSLAVEMODE_DISABLE;
  if (HAL_TIMEx_MasterConfigSynchronization(&htim3, &sMasterConfig) != HAL_OK)
  {
    Error_Handler();
  }
  sConfigOC.OCMode = TIM_OCMODE_PWM1;
  sConfigOC.Pulse = 500;
  sConfigOC.OCPolarity = TIM_OCPOLARITY_HIGH;
  sConfigOC.OCFastMode = TIM_OCFAST_DISABLE;
  if (HAL_TIM_PWM_ConfigChannel(&htim3, &sConfigOC, TIM_CHANNEL_3) != HAL_OK)
  {
    Error_Handler();
  }
  HAL_TIM_MspPostInit(&htim3);

}

static void MX_DMA_Init(void)
{

  /* DMA controller clock enable */
  __HAL_RCC_DMA2_CLK_ENABLE();

  /* DMA interrupt init */
  /* DMA2_Stream0_IRQn interrupt configuration */
  HAL_NVIC_SetPriority(DMA2_Stream0_IRQn, 5, 0);
  HAL_NVIC_EnableIRQ(DMA2_Stream0_IRQn);

}

/* FMC initialization function */
static void MX_FMC_Init(void)
{

  FMC_SDRAM_TimingTypeDef SdramTiming = {0};

  /** Perform the SDRAM1 memory initialization sequence
  */
  hsdram1.Instance = FMC_SDRAM_DEVICE;
  /* hsdram1.Init */
  hsdram1.Init.SDBank = FMC_SDRAM_BANK2;
  hsdram1.Init.ColumnBitsNumber = FMC_SDRAM_COLUMN_BITS_NUM_8;
  hsdram1.Init.RowBitsNumber = FMC_SDRAM_ROW_BITS_NUM_12;
  hsdram1.Init.MemoryDataWidth = FMC_SDRAM_MEM_BUS_WIDTH_16;
  hsdram1.Init.InternalBankNumber = FMC_SDRAM_INTERN_BANKS_NUM_4;
  hsdram1.Init.CASLatency = FMC_SDRAM_CAS_LATENCY_3;
  hsdram1.Init.WriteProtection = FMC_SDRAM_WRITE_PROTECTION_DISABLE;
  hsdram1.Init.SDClockPeriod = FMC_SDRAM_CLOCK_PERIOD_2;
  hsdram1.Init.ReadBurst = FMC_SDRAM_RBURST_DISABLE;
  hsdram1.Init.ReadPipeDelay = FMC_SDRAM_RPIPE_DELAY_1;
  /* SdramTiming */
  SdramTiming.LoadToActiveDelay = 2;
  SdramTiming.ExitSelfRefreshDelay = 7;
  SdramTiming.SelfRefreshTime = 4;
  SdramTiming.RowCycleDelay = 7;
  SdramTiming.WriteRecoveryTime = 3;
  SdramTiming.RPDelay = 2;
  SdramTiming.RCDDelay = 2;

  if (HAL_SDRAM_Init(&hsdram1, &SdramTiming) != HAL_OK)
  {
    Error_Handler( );
  }

  /* USER CODE BEGIN FMC_Init 2 */

  FMC_SDRAM_CommandTypeDef command;

  /* Program the SDRAM external device */
  BSP_SDRAM_Initialization_Sequence(&hsdram1, &command);
  /* USER CODE END FMC_Init 2 */
}

static void MX_GPIO_Init(void)
{
  GPIO_InitTypeDef GPIO_InitStruct = {0};

  /* GPIO Ports Clock Enable */
  __HAL_RCC_GPIOE_CLK_ENABLE();
  __HAL_RCC_GPIOF_CLK_ENABLE();
  __HAL_RCC_GPIOH_CLK_ENABLE();
  __HAL_RCC_GPIOC_CLK_ENABLE();
  __HAL_RCC_GPIOA_CLK_ENABLE();
  __HAL_RCC_GPIOB_CLK_ENABLE();
  __HAL_RCC_GPIOG_CLK_ENABLE();
  __HAL_RCC_GPIOD_CLK_ENABLE();

  /*Configure GPIO pin Output Level */
  HAL_GPIO_WritePin(GPIOE, VSYNC_FREQ_Pin|RENDER_TIME_Pin|FRAME_RATE_Pin|MCU_ACTIVE_Pin, GPIO_PIN_RESET);

  /*Configure GPIO pin Output Level */
  HAL_GPIO_WritePin(SPI5_NCS_GPIO_Port, SPI5_NCS_Pin, GPIO_PIN_SET);

  /*Configure GPIO pin Output Level */
  HAL_GPIO_WritePin(GPIOC, GPIO_PIN_2, GPIO_PIN_RESET);

  /*Configure GPIO pin Output Level */
  HAL_GPIO_WritePin(GPIOD, GPIO_PIN_12|GPIO_PIN_13, GPIO_PIN_RESET);

  /*Configure GPIO pin Output Level */
  HAL_GPIO_WritePin(GPIOG, LED_GREEN_Pin|LED_RED_Pin, GPIO_PIN_RESET);

  /*Configure GPIO pins : VSYNC_FREQ_Pin RENDER_TIME_Pin FRAME_RATE_Pin MCU_ACTIVE_Pin */
  GPIO_InitStruct.Pin = VSYNC_FREQ_Pin|RENDER_TIME_Pin|FRAME_RATE_Pin|MCU_ACTIVE_Pin;
  GPIO_InitStruct.Mode = GPIO_MODE_OUTPUT_PP;
  GPIO_InitStruct.Pull = GPIO_NOPULL;
  GPIO_InitStruct.Speed = GPIO_SPEED_FREQ_VERY_HIGH;
  HAL_GPIO_Init(GPIOE, &GPIO_InitStruct);

  /*Configure GPIO pin : SPI5_NCS_Pin */
  GPIO_InitStruct.Pin = SPI5_NCS_Pin;
  GPIO_InitStruct.Mode = GPIO_MODE_OUTPUT_PP;
  GPIO_InitStruct.Pull = GPIO_NOPULL;
  GPIO_InitStruct.Speed = GPIO_SPEED_FREQ_LOW;
  HAL_GPIO_Init(SPI5_NCS_GPIO_Port, &GPIO_InitStruct);

  /*Configure GPIO pin : PC2 */
  GPIO_InitStruct.Pin = GPIO_PIN_2;
  GPIO_InitStruct.Mode = GPIO_MODE_OUTPUT_PP;
  GPIO_InitStruct.Pull = GPIO_NOPULL;
  GPIO_InitStruct.Speed = GPIO_SPEED_FREQ_HIGH;
  HAL_GPIO_Init(GPIOC, &GPIO_InitStruct);

  /*Configure GPIO pin : BTN_PAUSE_Pin */
  GPIO_InitStruct.Pin = BTN_PAUSE_Pin;
  GPIO_InitStruct.Mode = GPIO_MODE_INPUT;
  GPIO_InitStruct.Pull = GPIO_NOPULL;
  HAL_GPIO_Init(BTN_PAUSE_GPIO_Port, &GPIO_InitStruct);

  /*Configure GPIO pins : PD12 PD13 */
  GPIO_InitStruct.Pin = GPIO_PIN_12|GPIO_PIN_13;
  GPIO_InitStruct.Mode = GPIO_MODE_OUTPUT_PP;
  GPIO_InitStruct.Pull = GPIO_NOPULL;
  GPIO_InitStruct.Speed = GPIO_SPEED_FREQ_HIGH;
  HAL_GPIO_Init(GPIOD, &GPIO_InitStruct);

  /*Configure GPIO pins : BTN_LEFT_Pin BTN_RIGHT_Pin JOY_SW_Pin */
  GPIO_InitStruct.Pin = BTN_LEFT_Pin|BTN_RIGHT_Pin|JOY_SW_Pin;
  GPIO_InitStruct.Mode = GPIO_MODE_INPUT;
  GPIO_InitStruct.Pull = GPIO_PULLUP;
  HAL_GPIO_Init(GPIOG, &GPIO_InitStruct);

  /*Configure GPIO pins : BTN_ROT_CW_Pin BTN_ROT_CCW2_Pin */
  GPIO_InitStruct.Pin = BTN_ROT_CW_Pin|BTN_ROT_CCW2_Pin;
  GPIO_InitStruct.Mode = GPIO_MODE_INPUT;
  GPIO_InitStruct.Pull = GPIO_PULLUP;
  HAL_GPIO_Init(GPIOC, &GPIO_InitStruct);

  /*Configure GPIO pins : BTN_SOFT_Pin BTN_ROT_CCW_Pin BTN_HOLD_Pin BTN_HARD_Pin */
  GPIO_InitStruct.Pin = BTN_SOFT_Pin|BTN_ROT_CCW_Pin|BTN_HOLD_Pin|BTN_HARD_Pin;
  GPIO_InitStruct.Mode = GPIO_MODE_INPUT;
  GPIO_InitStruct.Pull = GPIO_PULLUP;
  HAL_GPIO_Init(GPIOD, &GPIO_InitStruct);

  /*Configure GPIO pins : LED_GREEN_Pin LED_RED_Pin */
  GPIO_InitStruct.Pin = LED_GREEN_Pin|LED_RED_Pin;
  GPIO_InitStruct.Mode = GPIO_MODE_OUTPUT_PP;
  GPIO_InitStruct.Pull = GPIO_NOPULL;
  GPIO_InitStruct.Speed = GPIO_SPEED_FREQ_LOW;
  HAL_GPIO_Init(GPIOG, &GPIO_InitStruct);

  /*Configure GPIO pin : BTN_HOLD2_Pin */
  GPIO_InitStruct.Pin = BTN_HOLD2_Pin;
  GPIO_InitStruct.Mode = GPIO_MODE_INPUT;
  GPIO_InitStruct.Pull = GPIO_PULLUP;
  HAL_GPIO_Init(BTN_HOLD2_GPIO_Port, &GPIO_InitStruct);

}

/* USER CODE BEGIN 4 */
/**
  * @brief  Perform the SDRAM external memory initialization sequence
  * @param  hsdram: SDRAM handle
  * @param  Command: Pointer to SDRAM command structure
  * @retval None
  */
static void BSP_SDRAM_Initialization_Sequence(SDRAM_HandleTypeDef *hsdram, FMC_SDRAM_CommandTypeDef *Command)
{
 __IO uint32_t tmpmrd =0;

  /* Step 1:  Configure a clock configuration enable command */
  Command->CommandMode             = FMC_SDRAM_CMD_CLK_ENABLE;
  Command->CommandTarget           = FMC_SDRAM_CMD_TARGET_BANK2;
  Command->AutoRefreshNumber       = 1;
  Command->ModeRegisterDefinition  = 0;

  /* Send the command */
  HAL_SDRAM_SendCommand(hsdram, Command, SDRAM_TIMEOUT);

  /* Step 2: Insert 100 us minimum delay */
  /* Inserted delay is equal to 1 ms due to systick time base unit (ms) */
  HAL_Delay(1);

  /* Step 3: Configure a PALL (precharge all) command */
  Command->CommandMode             = FMC_SDRAM_CMD_PALL;
  Command->CommandTarget           = FMC_SDRAM_CMD_TARGET_BANK2;
  Command->AutoRefreshNumber       = 1;
  Command->ModeRegisterDefinition  = 0;

  /* Send the command */
  HAL_SDRAM_SendCommand(hsdram, Command, SDRAM_TIMEOUT);

  /* Step 4: Configure an Auto Refresh command */
  Command->CommandMode             = FMC_SDRAM_CMD_AUTOREFRESH_MODE;
  Command->CommandTarget           = FMC_SDRAM_CMD_TARGET_BANK2;
  Command->AutoRefreshNumber       = 4;
  Command->ModeRegisterDefinition  = 0;

  /* Send the command */
  HAL_SDRAM_SendCommand(hsdram, Command, SDRAM_TIMEOUT);

  /* Step 5: Program the external memory mode register */
  tmpmrd = (uint32_t)SDRAM_MODEREG_BURST_LENGTH_1          |
                     SDRAM_MODEREG_BURST_TYPE_SEQUENTIAL   |
                     SDRAM_MODEREG_CAS_LATENCY_3           |
                     SDRAM_MODEREG_OPERATING_MODE_STANDARD |
                     SDRAM_MODEREG_WRITEBURST_MODE_SINGLE;

  Command->CommandMode             = FMC_SDRAM_CMD_LOAD_MODE;
  Command->CommandTarget           = FMC_SDRAM_CMD_TARGET_BANK2;
  Command->AutoRefreshNumber       = 1;
  Command->ModeRegisterDefinition  = tmpmrd;

  /* Send the command */
  HAL_SDRAM_SendCommand(hsdram, Command, SDRAM_TIMEOUT);

  /* Step 6: Set the refresh rate counter */
  /* Set the device refresh rate */
  HAL_SDRAM_ProgramRefreshRate(hsdram, REFRESH_COUNT);
}

/**
  * @brief  IOE Low Level Initialization.
  */
void IOE_Init(void)
{
  //Dummy function called when initializing to stmpe811 to setup the i2c.
  //This is done with cubmx and is therfore not done here.
}

/**
  * @brief  IOE Low Level Interrupt configuration.
  */
void IOE_ITConfig(void)
{
  //Dummy function called when initializing to stmpe811 to setup interupt for the i2c.
  //The interupt is not used in our case, therefore nothing is done here.
}

/**
  * @brief  IOE Writes single data operation.
  * @param  Addr: I2C Address
  * @param  Reg: Reg Address
  * @param  Value: Data to be written
  */
void IOE_Write(uint8_t Addr, uint8_t Reg, uint8_t Value)
{
  I2C3_WriteData(Addr, Reg, Value);
}

/**
  * @brief  IOE Reads single data.
  * @param  Addr: I2C Address
  * @param  Reg: Reg Address
  * @retval The read data
  */
uint8_t IOE_Read(uint8_t Addr, uint8_t Reg)
{
  return I2C3_ReadData(Addr, Reg);
}

/**
  * @brief  IOE Reads multiple data.
  * @param  Addr: I2C Address
  * @param  Reg: Reg Address
  * @param  pBuffer: pointer to data buffer
  * @param  Length: length of the data
  * @retval 0 if no problems to read multiple data
  */
uint16_t IOE_ReadMultiple(uint8_t Addr, uint8_t Reg, uint8_t *pBuffer, uint16_t Length)
{
 return I2C3_ReadBuffer(Addr, Reg, pBuffer, Length);
}

/**
  * @brief  IOE Delay.
  * @param  Delay in ms
  */
void IOE_Delay(uint32_t Delay)
{
  HAL_Delay(Delay);
}

/**
  * @brief  Writes a value in a register of the device through BUS.
  * @param  Addr: Device address on BUS Bus.
  * @param  Reg: The target register address to write
  * @param  Value: The target register value to be written
  */
static void I2C3_WriteData(uint8_t Addr, uint8_t Reg, uint8_t Value)
{
  HAL_StatusTypeDef status = HAL_OK;

  status = HAL_I2C_Mem_Write(&hi2c3, Addr, (uint16_t)Reg, I2C_MEMADD_SIZE_8BIT, &Value, 1, I2c3Timeout);

  /* Check the communication status */
  if(status != HAL_OK)
  {
    /* Re-Initialize the BUS */
    //I2Cx_Error();
  }
}

/**
  * @brief  Reads a register of the device through BUS.
  * @param  Addr: Device address on BUS Bus.
  * @param  Reg: The target register address to write
  * @retval Data read at register address
  */
static uint8_t I2C3_ReadData(uint8_t Addr, uint8_t Reg)
{
  HAL_StatusTypeDef status = HAL_OK;
  uint8_t value = 0;

  status = HAL_I2C_Mem_Read(&hi2c3, Addr, Reg, I2C_MEMADD_SIZE_8BIT, &value, 1, I2c3Timeout);

  /* Check the communication status */
  if(status != HAL_OK)
  {
    /* Re-Initialize the BUS */
    //I2Cx_Error();

  }
  return value;
}

/**
  * @brief  Reads multiple data on the BUS.
  * @param  Addr: I2C Address
  * @param  Reg: Reg Address
  * @param  pBuffer: pointer to read data buffer
  * @param  Length: length of the data
  * @retval 0 if no problems to read multiple data
  */
static uint8_t I2C3_ReadBuffer(uint8_t Addr, uint8_t Reg, uint8_t *pBuffer, uint16_t Length)
{
  HAL_StatusTypeDef status = HAL_OK;

  status = HAL_I2C_Mem_Read(&hi2c3, Addr, (uint16_t)Reg, I2C_MEMADD_SIZE_8BIT, pBuffer, Length, I2c3Timeout);

  /* Check the communication status */
  if(status == HAL_OK)
  {
    return 0;
  }
  else
  {
    /* Re-Initialize the BUS */
    //I2Cx_Error();

    return 1;
  }
}

/**
  * @brief  Reads 4 bytes from device.
  * @param  ReadSize: Number of bytes to read (max 4 bytes)
  * @retval Value read on the SPI
  */
static uint32_t SPI5_Read(uint8_t ReadSize)
{
  HAL_StatusTypeDef status = HAL_OK;
  uint32_t readvalue;

  status = HAL_SPI_Receive(&hspi5, (uint8_t*) &readvalue, ReadSize, Spi5Timeout);

  /* Check the communication status */
  if(status != HAL_OK)
  {
    /* Re-Initialize the BUS */
    SPI5_Error();
  }

  return readvalue;
}

/**
  * @brief  Writes a byte to device.
  * @param  Value: value to be written
  */
static void SPI5_Write(uint16_t Value)
{
  HAL_StatusTypeDef status = HAL_OK;

  status = HAL_SPI_Transmit(&hspi5, (uint8_t*) &Value, 1, Spi5Timeout);

  /* Check the communication status */
  if(status != HAL_OK)
  {
    /* Re-Initialize the BUS */
    SPI5_Error();
  }
}

/**
  * @brief  SPI5 error treatment function.
  */
static void SPI5_Error(void)
{
  /* De-initialize the SPI communication BUS */
  //HAL_SPI_DeInit(&SpiHandle);

  /* Re- Initialize the SPI communication BUS */
  //SPIx_Init();
}

void LCD_IO_Init(void)
{
  /* Set or Reset the control line */
  HAL_GPIO_WritePin(GPIOC, GPIO_PIN_2, GPIO_PIN_RESET);
  HAL_GPIO_WritePin(GPIOC, GPIO_PIN_2, GPIO_PIN_SET);
}

/**
  * @brief  Writes register value.
  */
void LCD_IO_WriteData(uint16_t RegValue)
{
  /* Set WRX to send data */
  HAL_GPIO_WritePin(GPIOD, GPIO_PIN_13, GPIO_PIN_SET);

  /* Reset LCD control line(/CS) and Send data */
  HAL_GPIO_WritePin(GPIOC, GPIO_PIN_2, GPIO_PIN_RESET);
  SPI5_Write(RegValue);

  /* Deselect: Chip Select high */
  HAL_GPIO_WritePin(GPIOC, GPIO_PIN_2, GPIO_PIN_SET);
}

/**
  * @brief  Writes register address.
  */
void LCD_IO_WriteReg(uint8_t Reg)
{
  /* Reset WRX to send command */
  HAL_GPIO_WritePin(GPIOD, GPIO_PIN_13, GPIO_PIN_RESET);

  /* Reset LCD control line(/CS) and Send command */
  HAL_GPIO_WritePin(GPIOC, GPIO_PIN_2, GPIO_PIN_RESET);
  SPI5_Write(Reg);

  /* Deselect: Chip Select high */
  HAL_GPIO_WritePin(GPIOC, GPIO_PIN_2, GPIO_PIN_SET);
}

/**
  * @brief  Reads register value.
  * @param  RegValue Address of the register to read
  * @param  ReadSize Number of bytes to read
  * @retval Content of the register value
  */
uint32_t LCD_IO_ReadData(uint16_t RegValue, uint8_t ReadSize)
{
  uint32_t readvalue = 0;

  /* Select: Chip Select low */
  HAL_GPIO_WritePin(GPIOC, GPIO_PIN_2, GPIO_PIN_RESET);

  /* Reset WRX to send command */
  HAL_GPIO_WritePin(GPIOD, GPIO_PIN_13, GPIO_PIN_RESET);

  SPI5_Write(RegValue);

  readvalue = SPI5_Read(ReadSize);

  /* Set WRX to send data */
  HAL_GPIO_WritePin(GPIOD, GPIO_PIN_13, GPIO_PIN_SET);

  /* Deselect: Chip Select high */
  HAL_GPIO_WritePin(GPIOC, GPIO_PIN_2, GPIO_PIN_SET);

  return readvalue;
}

/**
  * @brief  Wait for loop in ms.
  * @param  Delay in ms.
  */
void LCD_Delay(uint32_t Delay)
{
  HAL_Delay(Delay);
}

/* RNG phần cứng cho game Tetris (thuật toán 7-bag) — gọi từ TetrisGame (C++) qua extern "C".
   Đây là Yêu cầu ① của BTL: sinh ngẫu nhiên bằng peripheral RNG, KHÔNG dùng rand()/LCG.
   Lỗi seed/clock của RNG rất hiếm nhưng để chắc chắn KHÔNG bao giờ trả về giá trị cố định
   (làm xáo trộn 7-bag suy biến), ta thử lại có giới hạn + re-init RNG khi lỗi. Mọi đường
   đều là RNG phần cứng — không hề rơi về random phần mềm. */
uint32_t hw_rand(void)
{
  uint32_t v = 0;
  for (int tries = 0; tries < 10; tries++)
  {
    if (HAL_RNG_GenerateRandomNumber(&hrng, &v) == HAL_OK)
      return v;                 /* lấy được số ngẫu nhiên phần cứng -> trả ngay */
    /* hiếm: cờ lỗi seed/clock bị chốt -> khởi tạo lại peripheral để xoá lỗi rồi thử tiếp */
    HAL_RNG_DeInit(&hrng);
    HAL_RNG_Init(&hrng);
  }
  return v;                     /* cực hiếm: RNG hỏng hẳn (HAL_RNG_Init lúc khởi động đã Error_Handler) */
}

/* ============== P6: ÂM THANH — buzzer thụ động qua TIM3_CH3 PWM (Yêu cầu ②) ============== */
typedef struct { uint16_t freq; uint16_t ms; } Note; /* freq=0: nghỉ; ms=0: kết thúc dãy */

/* Phát 1 nốt tần số f (Hz). f=0 -> im. Tick TIM3 = 90MHz/(PSC+1) = 1 MHz */
void buzzer_tone(uint32_t freq)
{
  if (freq == 0)
  {
    __HAL_TIM_SET_COMPARE(&htim3, TIM_CHANNEL_3, 0); /* duty 0 = tắt tiếng */
    return;
  }
  /* Clock timer APB1 = PCLK1 ×(2 nếu APB1 prescaler != 1). Lấy động từ HAL để KHÔNG
     phụ thuộc số cứng — nếu sau này đổi cây clock thì tần số nốt vẫn đúng. */
  uint32_t pclk1 = HAL_RCC_GetPCLK1Freq();
  uint32_t timerClk = ((RCC->CFGR & RCC_CFGR_PPRE1) == 0u) ? pclk1 : (pclk1 * 2u);
  uint32_t tickHz = timerClk / (htim3.Init.Prescaler + 1);
  uint32_t arr = tickHz / freq;
  if (arr < 2) arr = 2;
  __HAL_TIM_SET_AUTORELOAD(&htim3, arr - 1);
  __HAL_TIM_SET_COMPARE(&htim3, TIM_CHANNEL_3, arr / 2); /* duty 50% */
}

/* Phát một dãy nốt (kết thúc khi gặp ms==0) */
static void play_notes(const Note* seq)
{
  for (int i = 0; seq[i].ms != 0; i++)
  {
    buzzer_tone(seq[i].freq);
    osDelay(seq[i].ms);
  }
  buzzer_tone(0);
}

/* SFX ngắn cho từng sự kiện */
static const Note SFX_MOVE[]     = { {1200, 18}, {0, 0} };
static const Note SFX_ROTATE[]   = { {1600, 28}, {0, 0} };
static const Note SFX_LOCK[]     = { {300, 28},  {0, 0} };
static const Note SFX_LINE[]     = { {784, 60}, {1047, 90}, {0, 0} };
static const Note SFX_TETRIS[]   = { {784, 70}, {988, 70}, {1175, 70}, {1568, 180}, {0, 0} };
static const Note SFX_LEVELUP[]  = { {1047, 60}, {1319, 60}, {1568, 140}, {0, 0} };
static const Note SFX_GAMEOVER[] = { {440, 160}, {370, 160}, {294, 160}, {220, 320}, {0, 0} };

static const Note* sfx_for(uint8_t id)
{
  switch (id) /* KHỚP enum tetris::Sound */
  {
  case 0:  return SFX_MOVE;
  case 1:  return SFX_ROTATE;
  case 2:  return SFX_LOCK;
  case 3:  return SFX_LINE;
  case 4:  return SFX_TETRIS;
  case 5:  return SFX_LEVELUP;
  case 6:  return SFX_GAMEOVER;
  default: return SFX_MOVE;
  }
}

/* Nhạc nền Korobeiniki (giai điệu Tetris cổ điển). q=400ms, e=200ms */
static const Note KOROBEINIKI[] = {
  {659,400},{494,200},{523,200},{587,400},{523,200},{494,200},
  {440,400},{440,200},{523,200},{659,400},{587,200},{523,200},
  {494,600},{523,200},{587,400},{659,400},
  {523,400},{440,400},{440,400},{0,200},
  {587,600},{698,200},{880,400},{784,200},{698,200},
  {659,600},{523,200},{659,400},{587,200},{523,200},
  {494,400},{494,200},{523,200},{587,400},{659,400},
  {523,400},{440,400},{440,400},{0,400},
};

/* Hàm cầu nối: TetrisGame (C++) đẩy sự kiện âm vào hàng đợi */
void sound_emit(uint8_t id)
{
  if (soundQueueHandle == NULL || !g_soundOn)
    return; /* đang tắt tiếng -> không đẩy */
  /* Chống ngập (PvP 2 người bấm dồn): khi hàng đợi gần đầy, bỏ qua âm PHỤ
     (0=move,1=rotate,2=lock) để luôn còn chỗ cho âm QUAN TRỌNG (line/tetris/levelup/gameover). */
  if (id <= 2u && osMessageQueueGetSpace(soundQueueHandle) < 4u)
    return;
  osMessageQueuePut(soundQueueHandle, &id, 0, 0);
}

/* Hàm cầu nối: View (C++) bật/tắt nhạc nền khi Pause/Resume */
void set_music_paused(uint8_t paused)
{
  g_musicPaused = paused ? 1 : 0;
}

/* Hàm cầu nối: View (C++) bật/tắt tiếng (nút HOLD khi ở Menu).
   LED báo trạng thái: xanh (PG13) = có tiếng, đỏ (PG14) = tắt tiếng. */
void set_sound_on(uint8_t on)
{
  g_soundOn = on ? 1 : 0;
  HAL_GPIO_WritePin(LED_GREEN_GPIO_Port, LED_GREEN_Pin, g_soundOn ? GPIO_PIN_SET : GPIO_PIN_RESET);
  HAL_GPIO_WritePin(LED_RED_GPIO_Port,   LED_RED_Pin,   g_soundOn ? GPIO_PIN_RESET : GPIO_PIN_SET);
  if (!g_soundOn)
    buzzer_tone(0); /* tắt ngay tiếng đang phát */
}

/* Hàm cầu nối: View (C++) bật/tắt chế độ 2 người -> InputTask tách nút/joystick */
void set_pvp_mode(uint8_t on)
{
  g_pvpMode = on ? 1 : 0;
}

/* ============== P8: LƯU ĐIỂM CAO VÀO FLASH NỘI (giữ qua tắt nguồn) ==============
   Dùng sector 23 (bank 2, 0x081E0000, 128KB) — KHÔNG chứa code/asset (chương trình
   nằm trọn ở bank 1, ~150KB). F429 2MB là dual-bank: xoá/ghi bank 2 trong khi CPU
   vẫn nạp lệnh ở bank 1 KHÔNG bị treo (read-while-write) -> màn hình không khựng. */
#define HISCORE_ADDR   0x081E0000UL
#define HISCORE_MAGIC  0x54455452UL  /* 'TETR' - nhận biết dữ liệu hợp lệ */

/* Đọc 4 điểm cao (4 chế độ) từ Flash. Lần đầu (chưa có magic) -> trả 0. */
void hiscore_load(uint32_t* out4)
{
  const volatile uint32_t* p = (const volatile uint32_t*)HISCORE_ADDR;
  if (p[0] == HISCORE_MAGIC)
  {
    for (int i = 0; i < 4; i++) out4[i] = p[1 + i];
  }
  else
  {
    for (int i = 0; i < 4; i++) out4[i] = 0;
  }
}

/* Xoá sector 23 rồi ghi magic + 4 điểm cao. Chỉ gọi khi có kỷ lục mới (hiếm). */
void hiscore_save(const uint32_t* in4)
{
  FLASH_EraseInitTypeDef er;
  uint32_t secErr = 0;

  HAL_FLASH_Unlock();
  er.TypeErase    = FLASH_TYPEERASE_SECTORS;
  er.Sector       = FLASH_SECTOR_23;
  er.NbSectors    = 1;
  er.VoltageRange = FLASH_VOLTAGE_RANGE_3; /* 2.7-3.6V -> ghi từng word 32-bit */
  if (HAL_FLASHEx_Erase(&er, &secErr) == HAL_OK)
  {
    HAL_FLASH_Program(FLASH_TYPEPROGRAM_WORD, HISCORE_ADDR, HISCORE_MAGIC);
    for (int i = 0; i < 4; i++)
      HAL_FLASH_Program(FLASH_TYPEPROGRAM_WORD, HISCORE_ADDR + 4u + (uint32_t)i * 4u, in4[i]);
  }
  HAL_FLASH_Lock();
}

/* AudioTask: phát nhạc nền lặp; có SFX trong hàng đợi thì chen ngang phát trước */
void StartAudioTask(void *argument)
{
  (void)argument;
  const uint32_t melodyLen = sizeof(KOROBEINIKI) / sizeof(KOROBEINIKI[0]);
  uint32_t mi = 0;
  for (;;)
  {
    uint8_t sid;
    if (soundQueueHandle != NULL && osMessageQueueGet(soundQueueHandle, &sid, NULL, 0) == osOK)
    {
      if (g_soundOn) play_notes(sfx_for(sid)); /* SFX chen ngang; bỏ qua nếu đang tắt tiếng */
    }

    if (g_soundOn && !g_musicPaused)
    {
      Note n = KOROBEINIKI[mi];
      buzzer_tone(n.freq);
      osDelay(n.ms);
      buzzer_tone(0);
      osDelay(12); /* nghỉ ngắn giữa các nốt */
      if (++mi >= melodyLen) mi = 0;
    }
    else
    {
      buzzer_tone(0); /* tắt tiếng khi tắt nhạc hoặc đang Pause */
      osDelay(40);
    }
  }
}

/* USER CODE END 4 */

void StartDefaultTask(void *argument)
{
  /* USER CODE BEGIN 5 */
  /* ===== InputTask: đọc 8 nút + joystick mỗi ~15ms, debounce + DAS/ARR,
     đẩy lệnh vào inputQueueHandle. Mã 0..5 KHỚP tetris::Command
     (LEFT, RIGHT, ROT_CW, ROT_CCW, SOFT_DROP, HARD_DROP). ===== */
  enum { ACT_LEFT, ACT_RIGHT, ACT_ROT_CW, ACT_ROT_CCW, ACT_SOFT, ACT_HARD, ACT_COUNT };
  const int DAS_TICKS = 10;  /* giữ ~150ms rồi mới tự lặp */
  const int ARR_TICKS = 3;   /* lặp mỗi ~45ms */
  static const uint8_t repeatable[ACT_COUNT] = { 1, 1, 0, 0, 1, 0 }; /* L,R,SOFT lặp; xoay/hard 1 lần */
  uint16_t held[ACT_COUNT]  = { 0 }; /* 1 người: gộp; PvP: P1 (nút) */
  uint16_t heldB[ACT_COUNT] = { 0 }; /* PvP: P2 (joystick) */

  /* Infinite loop */
  for (;;)
  {
    /* Nút bấm (pull-up nội, nhấn = mức 0) */
    uint8_t bL    = (HAL_GPIO_ReadPin(BTN_LEFT_GPIO_Port,    BTN_LEFT_Pin)    == GPIO_PIN_RESET);
    uint8_t bR    = (HAL_GPIO_ReadPin(BTN_RIGHT_GPIO_Port,   BTN_RIGHT_Pin)   == GPIO_PIN_RESET);
    uint8_t bCW   = (HAL_GPIO_ReadPin(BTN_ROT_CW_GPIO_Port,  BTN_ROT_CW_Pin)  == GPIO_PIN_RESET);
    uint8_t bCCW  = (HAL_GPIO_ReadPin(BTN_ROT_CCW_GPIO_Port, BTN_ROT_CCW_Pin) == GPIO_PIN_RESET);
    uint8_t bSoft = (HAL_GPIO_ReadPin(BTN_SOFT_GPIO_Port,    BTN_SOFT_Pin)    == GPIO_PIN_RESET);
    uint8_t bHard = (HAL_GPIO_ReadPin(BTN_HARD_GPIO_Port,    BTN_HARD_Pin)    == GPIO_PIN_RESET);
    uint8_t bSW   = (HAL_GPIO_ReadPin(JOY_SW_GPIO_Port,      JOY_SW_Pin)      == GPIO_PIN_RESET);
    uint8_t bCCW2 = (HAL_GPIO_ReadPin(BTN_ROT_CCW2_GPIO_Port, BTN_ROT_CCW2_Pin) == GPIO_PIN_RESET); /* xoay-ngược của P2 (PvP); 1 người -> CCW phụ */
    /* (BTN_HOLD P1 (PD5) + BTN_HOLD P2 (PB7) + BTN_PAUSE (PA0): xử lý sườn riêng bên dưới) */

    /* Joystick (0..4095, giữa ~2048) — ngưỡng + vùng chết; hướng Y chỉnh lại khi cắm thật */
    uint16_t vx = g_adcJoy[0];
    uint16_t vy = g_adcJoy[1];
    uint8_t jL = (vx < 1200), jR = (vx > 2900);
    uint8_t jDown = (vy > 2900), jUp = (vy < 1200);

    /* Tách 2 nguồn: nút bấm (P1) và joystick (P2). P2 xoay CW = nhấn cần (SW),
       xoay CCW = nút rời PC12 (BTN_ROT_CCW2). */
    uint8_t btn[ACT_COUNT];
    btn[ACT_LEFT] = bL; btn[ACT_RIGHT] = bR; btn[ACT_ROT_CW] = bCW;
    btn[ACT_ROT_CCW] = bCCW; btn[ACT_SOFT] = bSoft; btn[ACT_HARD] = bHard;
    uint8_t joy[ACT_COUNT];
    joy[ACT_LEFT] = jL; joy[ACT_RIGHT] = jR; joy[ACT_ROT_CW] = bSW;
    joy[ACT_ROT_CCW] = bCCW2; joy[ACT_SOFT] = jDown; joy[ACT_HARD] = jUp;

    for (int a = 0; a < ACT_COUNT; a++)
    {
      /* Nguồn 1: nút (P1 khi PvP) — ở chế độ 1 người gộp luôn joystick vào đây */
      uint8_t src1 = g_pvpMode ? btn[a] : (btn[a] || joy[a]);
      uint8_t emit1 = 0;
      if (src1)
      {
        if (held[a] == 0) emit1 = 1;
        else if (repeatable[a] && held[a] >= DAS_TICKS && ((held[a] - DAS_TICKS) % ARR_TICKS) == 0) emit1 = 1;
        if (held[a] < 0xFFFF) held[a]++;
      }
      else held[a] = 0;
      if (emit1 && inputQueueHandle != NULL)
      {
        uint8_t code = (uint8_t)a; /* P1 / 1 người: mã 0..5 */
        osMessageQueuePut(inputQueueHandle, &code, 0, 0);
      }

      /* Nguồn 2: joystick (chỉ khi PvP -> P2, mã 16..21) */
      uint8_t emit2 = 0;
      if (g_pvpMode && joy[a])
      {
        if (heldB[a] == 0) emit2 = 1;
        else if (repeatable[a] && heldB[a] >= DAS_TICKS && ((heldB[a] - DAS_TICKS) % ARR_TICKS) == 0) emit2 = 1;
        if (heldB[a] < 0xFFFF) heldB[a]++;
      }
      else heldB[a] = 0;
      if (emit2 && inputQueueHandle != NULL)
      {
        uint8_t code = (uint8_t)(16 + a); /* P2: mã 16..21 */
        osMessageQueuePut(inputQueueHandle, &code, 0, 0);
      }
    }

    /* Nút PAUSE (PA0 = USER, mức CAO khi nhấn, không pull): gửi 1 lần mỗi lần
       nhấn (phát hiện sườn lên) -> View bật/tắt tạm dừng. Mã 6 = CMD_PAUSE_CODE. */
    static uint8_t pausePrev = 0;
    uint8_t bPause = (HAL_GPIO_ReadPin(BTN_PAUSE_GPIO_Port, BTN_PAUSE_Pin) == GPIO_PIN_SET);
    if (bPause && !pausePrev && inputQueueHandle != NULL)
    {
      uint8_t code = 6; /* tetris::CMD_PAUSE_CODE */
      osMessageQueuePut(inputQueueHandle, &code, 0, 0);
    }
    pausePrev = bPause;

    /* Nút HOLD P1 (PD5, active-LOW): gửi 1 lần mỗi lần nhấn (sườn xuống). Khi đang chơi
       -> View cho P1 giữ khối; ở màn End -> chơi lại. Mã 7 = CMD_RESTART_CODE. */
    static uint8_t holdPrev = 0;
    uint8_t bHold = (HAL_GPIO_ReadPin(BTN_HOLD_GPIO_Port, BTN_HOLD_Pin) == GPIO_PIN_RESET);
    if (bHold && !holdPrev && inputQueueHandle != NULL)
    {
      uint8_t code = 7; /* tetris::CMD_RESTART_CODE */
      osMessageQueuePut(inputQueueHandle, &code, 0, 0);
    }
    holdPrev = bHold;

    /* Nút HOLD P2 (PB7, active-LOW): chỉ có ý nghĩa khi PvP -> joystick player giữ khối
       (View bỏ qua khi chơi 1 người). Sườn xuống -> mã 8 = CMD_HOLD_P2_CODE. */
    static uint8_t hold2Prev = 0;
    uint8_t bHold2 = (HAL_GPIO_ReadPin(BTN_HOLD2_GPIO_Port, BTN_HOLD2_Pin) == GPIO_PIN_RESET);
    if (bHold2 && !hold2Prev && inputQueueHandle != NULL)
    {
      uint8_t code = 8; /* tetris::CMD_HOLD_P2_CODE */
      osMessageQueuePut(inputQueueHandle, &code, 0, 0);
    }
    hold2Prev = bHold2;

    osDelay(15);
  }
  /* USER CODE END 5 */
}

void HAL_TIM_PeriodElapsedCallback(TIM_HandleTypeDef *htim)
{
  if (htim->Instance == TIM6)
  {
    HAL_IncTick();
  }
}

void Error_Handler(void)
{
}
